# APM32F411 register map
File version: 1.0
CPU: CM4 r1p0, little endian, no MPU, no FPU, 3 interrupt priority bits
Registers are 32-bit, read-write, reset 0x0 unless marked. A register's access mark holds for its fields unless they carry their own. Offsets are from the block's base; [hi:lo] are bit positions; {n}, {i} and the like mark numbered series; 'fields as' and 'values as' point back to an identical list.

## TMR10 — General-purpose-timers
Base 0x40014400
Same registers: TMR13 0x40001C00, TMR14 0x40002000
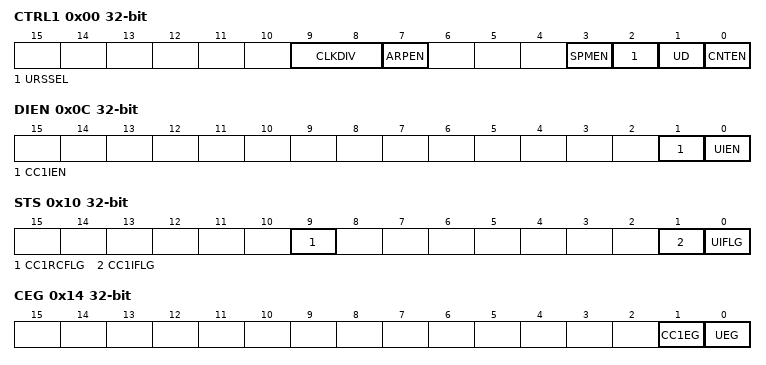
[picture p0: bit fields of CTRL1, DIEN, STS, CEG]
0x00 CTRL1 — control register 1
  [9:8] CLKDIV — Clock division
  [7] ARPEN — Auto-reload preload enable
  [3] SPMEN — Single Pulse Mode Enable
  [2] URSSEL — Update request source
  [1] UD — Update disable
  [0] CNTEN — Counter enable
0x0C DIEN — DMA/Interrupt enable register
  [1] CC1IEN — Capture/Compare 1 interrupt enable
  [0] UIEN — Update interrupt enable
0x10 STS — status register
  [9] CC1RCFLG — Capture/Compare 1 overcapture flag
  [1] CC1IFLG — Capture/compare 1 interrupt flag
  [0] UIFLG — Update interrupt flag
0x14 CEG wo — control event generation register
  [1] CC1EG — Capture/compare 1 generation
  [0] UEG — Update generation
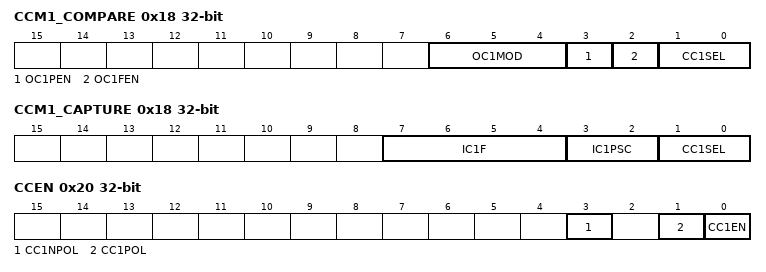
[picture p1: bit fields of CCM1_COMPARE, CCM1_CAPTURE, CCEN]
0x18 CCM1_COMPARE — capture/compare mode register 1 (output mode)
  [6:4] OC1MOD — Output Compare 1 mode
  [3] OC1PEN — Output Compare 1 preload enable
  [2] OC1FEN — Output Compare 1 fast enable
  [1:0] CC1SEL — Capture/Compare 1 selection
0x18 CCM1_CAPTURE (alternate view of CCM1_COMPARE) — capture/compare mode register 1 (input mode)
  [7:4] IC1F — Input capture 1 filter
  [3:2] IC1PSC — Input capture 1 prescaler
  [1:0] CC1SEL — Capture/Compare 1 selection
0x20 CCEN — capture/compare enable register
  [3] CC1NPOL — Capture/Compare 1 output Polarity
  [1] CC1POL — Capture/Compare 1 output Polarity
  [0] CC1EN — Capture/Compare 1 output enable
0x24 CNT — counter
  [15:0] CNT — counter value
0x28 PSC — prescaler
  [15:0] PSC — Prescaler value
0x2C AUTORLD reset 0xFFFF — auto-reload register
  [15:0] AUTORLD — Auto-reload value
0x34 CC1 — capture/compare register 1
  [15:0] CC1 — Capture/Compare 1 value

## TMR11 — General-purpose-timers
Base 0x40014800
Registers as TMR10; these are added or differ:
0x50 OPT — option register
  [1:0] RMPSEL — Input 1 remapping capability

## EINT — External interrupt/event controller
Base 0x40013C00
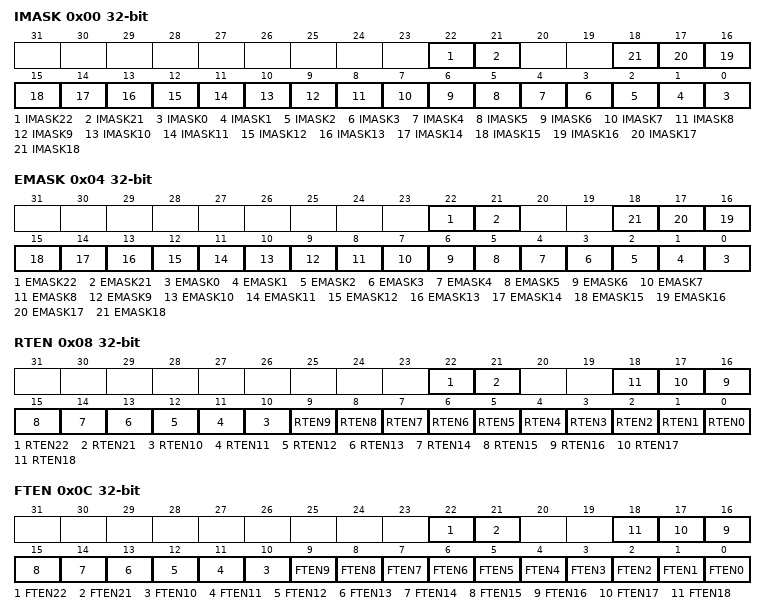
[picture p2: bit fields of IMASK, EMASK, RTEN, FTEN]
0x00 IMASK — Interrupt mask register
  [22] IMASK22 — Interrupt Mask on line 22
  [21] IMASK21 — Interrupt Mask on line 21
  [n] IMASK{n} (n=0..18) — Interrupt Mask on line {n}
0x04 EMASK — Event mask register
  [22] EMASK22 — Event Mask on line 22
  [21] EMASK21 — Event Mask on line 21
  [n] EMASK{n} (n=0..18) — Event Mask on line {n}
0x08 RTEN — Rising Trigger selection register
  [22] RTEN22 — Rising trigger event configuration of line 22
  [21] RTEN21 — Rising trigger event configuration of line 21
  [n] RTEN{n} (n=0..18) — Rising trigger event configuration of line {n}
0x0C FTEN — Falling Trigger selection register
  [22] FTEN22 — Falling trigger event configuration of line 22
  [21] FTEN21 — Falling trigger event configuration of line 21
  [n] FTEN{n} (n=0..18) — Falling trigger event configuration of line {n}
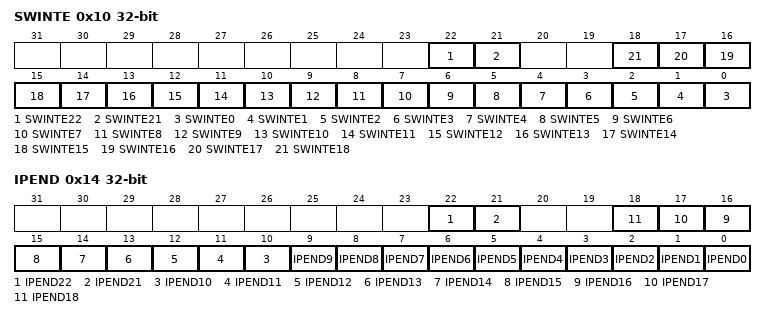
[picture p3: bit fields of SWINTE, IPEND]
0x10 SWINTE — Software interrupt event register
  [22] SWINTE22 — Software Interrupt on line 22
  [21] SWINTE21 — Software Interrupt on line 21
  [n] SWINTE{n} (n=0..18) — Software Interrupt on line {n}
0x14 IPEND — Pending register
  [22] IPEND22 — Pending bit 22
  [21] IPEND21 — Pending bit 21
  [n] IPEND{n} (n=0..18) — Pending bit {n}

## NVIC — Nested Vectored Interrupt Controller
Base 0xE000E100
{0x0+4i} ISER{i} (i=0..2) — Interrupt Set-Enable Register
  [31:0] SETENA
{0x80+4i} ICER{i} (i=0..2) — Interrupt Clear-Enable Register
  [31:0] CLRENA
{0x100+4i} ISPR{i} (i=0..2) — Interrupt Set-Pending Register
  [31:0] SETPEND
{0x180+4i} ICPR{i} (i=0..2) — Interrupt Clear-Pending Register
  [31:0] CLRPEND
{0x200+4i} IABR{i} ro (i=0..2) — Interrupt Active Bit Register
  [31:0] ACTIVE
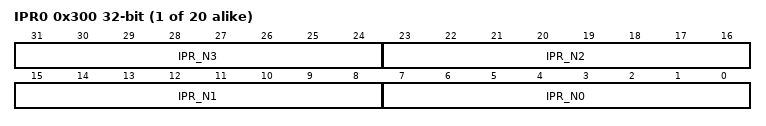
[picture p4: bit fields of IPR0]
{0x300+4i} IPR{i} (i=0..19) — Interrupt Priority Register
  [8n+7:8n] IPR_N{n} (n=0..3)

## OTG_FS_HOST — USB on the go full speed
Base 0x50000400
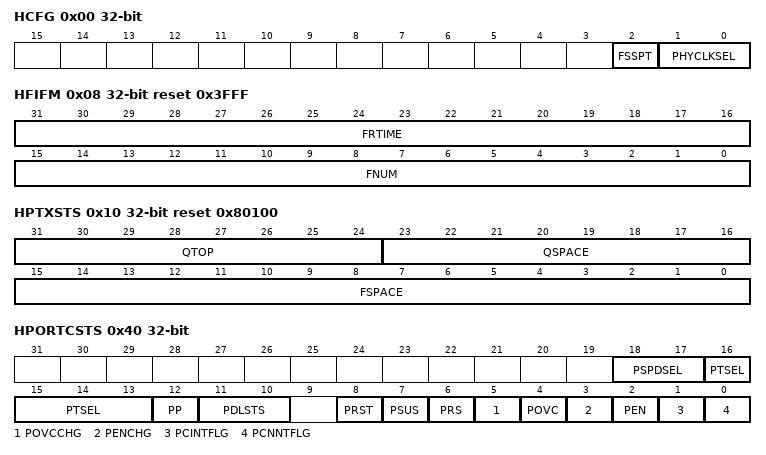
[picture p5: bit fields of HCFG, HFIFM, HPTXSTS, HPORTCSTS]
0x00 HCFG access per field — OTG_FS host configuration register (OTG_FS_HCFG)
  [2] FSSPT ro — FS- and LS-only support
  [1:0] PHYCLKSEL rw — FS/LS PHY clock select
0x04 HFIVL reset 0xEA60 — OTG_FS Host frame interval register
  [15:0] FIVL — Frame interval
0x08 HFIFM ro reset 0x3FFF — OTG_FS host frame number/frame time remaining register (OTG_FS_HFNUM)
  [31:16] FRTIME — Frame time remaining
  [15:0] FNUM — Frame number
0x10 HPTXSTS access per field reset 0x80100 — OTG_FS_Host periodic transmit FIFO/queue status register (OTG_FS_HPTXSTS)
  [31:24] QTOP ro — Top of the periodic transmit request queue
  [23:16] QSPACE ro — Periodic transmit request queue space available
  [15:0] FSPACE rw — Periodic transmit data FIFO space available
0x14 HACHINT ro — OTG_FS Host all channels interrupt register
  [15:0] ACHINT — Channel interrupts
0x18 HACHIMASK — OTG_FS host all channels interrupt mask register
  [15:0] ACHIMASK — Channel interrupt mask
0x40 HPORTCSTS access per field — OTG_FS host port control and status register (OTG_FS_HPRT)
  [18:17] PSPDSEL ro — Port speed
  [16:13] PTSEL rw — Port test control
  [12] PP rw — Port power
  [11:10] PDLSTS ro — Port line status
  [8] PRST rw — Port reset
  [7] PSUS rw — Port suspend
  [6] PRS rw — Port resume
  [5] POVCCHG rw — Port overcurrent change
  [4] POVC ro — Port overcurrent active
  [3] PENCHG rw — Port enable/disable change
  [2] PEN rw — Port enable
  [1] PCINTFLG rw — Port connect detected
  [0] PCNNTFLG ro — Port connect status
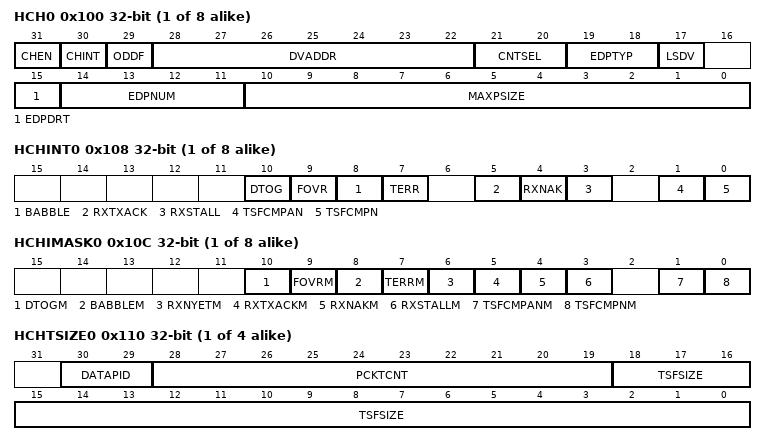
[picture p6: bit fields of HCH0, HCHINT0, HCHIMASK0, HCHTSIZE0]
{0x100+0x20*i} HCH{i} (i=0..7) — OTG_FS host channel-{i} characteristics register (OTG_FS_HCCHAR{i})
  [31] CHEN — Channel enable
  [30] CHINT — Channel disable
  [29] ODDF — Odd frame
  [28:22] DVADDR — Device address
  [21:20] CNTSEL — Multicount
  [19:18] EDPTYP — Endpoint type
  [17] LSDV — Low-speed device
  [15] EDPDRT — Endpoint direction
  [14:11] EDPNUM — Endpoint number
  [10:0] MAXPSIZE — Maximum packet size
{0x108+0x20*i} HCHINT{i} (i=0..7) — OTG_FS host channel-{i} interrupt register (OTG_FS_HCINT{i})
  [10] DTOG — Data toggle error
  [9] FOVR — Frame overrun
  [8] BABBLE — Babble error
  [7] TERR — Transaction error
  [5] RXTXACK — ACK response received/transmitted interrupt
  [4] RXNAK — NAK response received interrupt
  [3] RXSTALL — STALL response received interrupt
  [1] TSFCMPAN — Channel halted
  [0] TSFCMPN — Transfer completed
{0x10C+0x20*i} HCHIMASK{i} (i=0..7) — OTG_FS host channel-{i} mask register (OTG_FS_HCINTMSK{i})
  [10] DTOGM — Data toggle error mask
  [9] FOVRM — Frame overrun mask
  [8] BABBLEM — Babble error mask
  [7] TERRM — Transaction error mask
  [6] RXNYETM — response received interrupt mask
  [5] RXTXACKM — ACK response received/transmitted interrupt mask
  [4] RXNAKM — NAK response received interrupt mask
  [3] RXSTALLM — STALL response received interrupt mask
  [1] TSFCMPANM — Channel halted mask
  [0] TSFCMPNM — Transfer completed mask
{0x110+0x20*i} HCHTSIZE{i} (i=0..3) — OTG_FS host channel-{i} transfer size register
  [30:29] DATAPID
  [28:19] PCKTCNT — Packet count
  [18:0] TSFSIZE — Transfer size
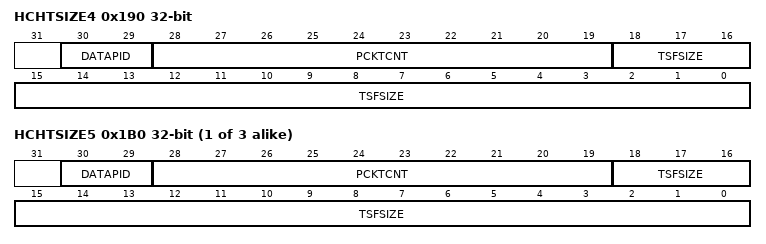
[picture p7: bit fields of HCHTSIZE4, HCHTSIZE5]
0x190 HCHTSIZE4 — OTG_FS host channel-x transfer size register
  fields as HCHTSIZE0
{0x110+0x20*i} HCHTSIZE{i} (i=5..7) — OTG_FS host channel-{i} transfer size register
  fields as HCHTSIZE0

## OTG_FS_PWRCLK — USB on the go full speed
Base 0x50000E00
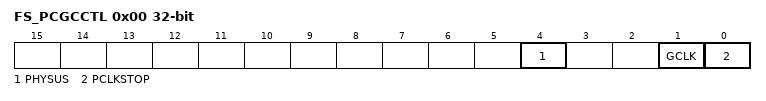
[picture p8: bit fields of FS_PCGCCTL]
0x00 FS_PCGCCTL — OTG_FS power and clock gating control register
  [4] PHYSUS — PHY Suspended
  [1] GCLK — Gate HCLK
  [0] PCLKSTOP — Stop PHY clock
